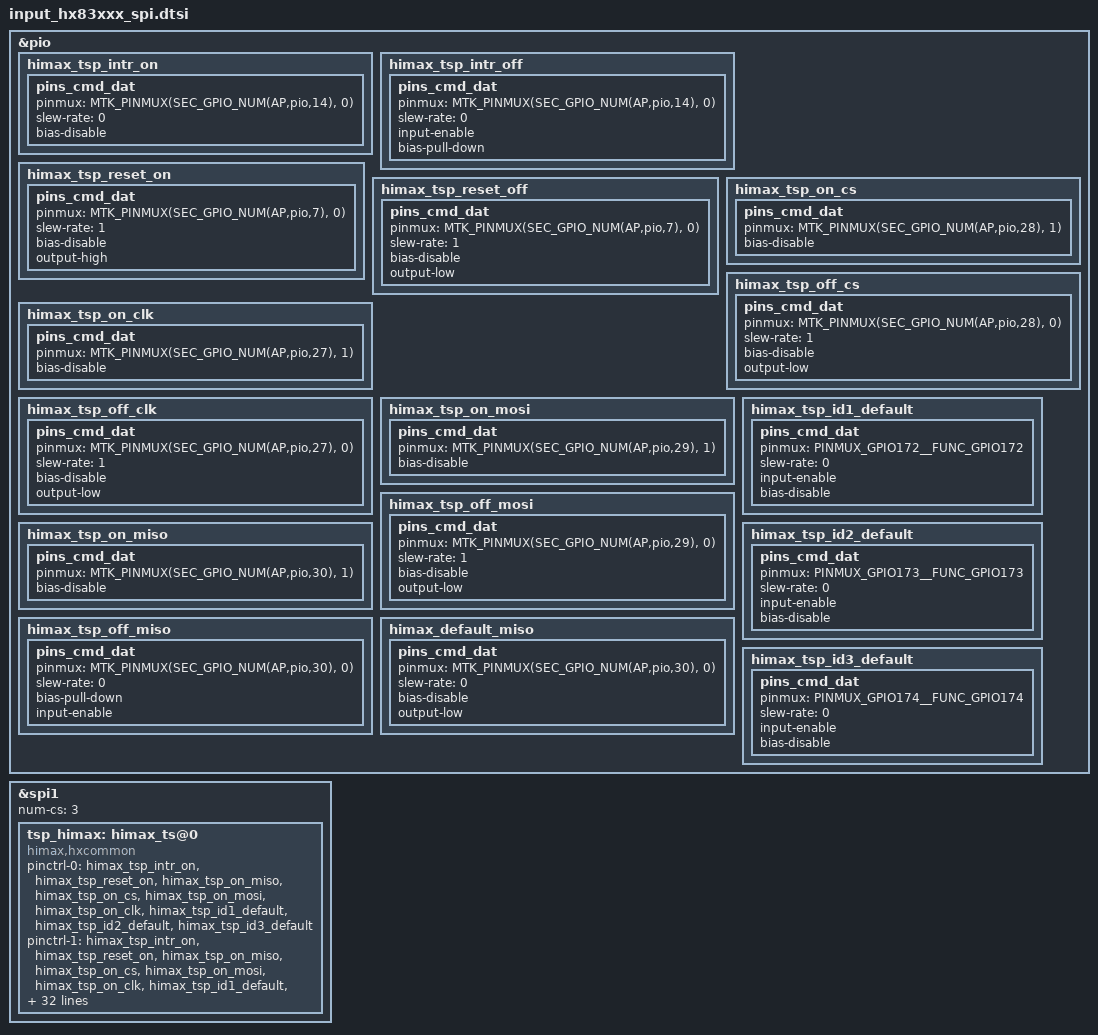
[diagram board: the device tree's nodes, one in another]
/* NEED TO FIX IF YOU WANT USE THIS */

&pio {
	himax_tsp_intr_on: himax_tsp_intr_on {
		pins_cmd_dat {
			pinmux = <MTK_PINMUX(SEC_GPIO_NUM(AP,pio,14), 0)>;
			slew-rate = <0>;
			bias-disable;
		};
	};

	himax_tsp_intr_off: himax_tsp_intr_off {
		pins_cmd_dat {
			pinmux = <MTK_PINMUX(SEC_GPIO_NUM(AP,pio,14), 0)>;
			slew-rate = <0>;
			input-enable;
			bias-pull-down;
		};
	};
};
&pio {
	himax_tsp_reset_on: himax_tsp_reset_on {
		pins_cmd_dat{
			pinmux = <MTK_PINMUX(SEC_GPIO_NUM(AP,pio,7), 0)>;
			slew-rate = <1>;
			bias-disable;
			output-high;
		};
	};

	himax_tsp_reset_off: himax_tsp_reset_off {
		pins_cmd_dat{
			pinmux = <MTK_PINMUX(SEC_GPIO_NUM(AP,pio,7), 0)>;
			slew-rate = <1>;
			bias-disable;
			output-low;
		};
	};
};
&pio {
	himax_tsp_on_cs: himax_tsp_on_cs {
		pins_cmd_dat{
			pinmux = <MTK_PINMUX(SEC_GPIO_NUM(AP,pio,28), 1)>;
			bias-disable;
		};
	};
	himax_tsp_off_cs: himax_tsp_off_cs {
		pins_cmd_dat{
			pinmux = <MTK_PINMUX(SEC_GPIO_NUM(AP,pio,28), 0)>;
			slew-rate = <1>;
			bias-disable;
			output-low;
		};
	};
};
&pio {
	himax_tsp_on_clk: himax_tsp_on_clk {
		pins_cmd_dat{
			pinmux = <MTK_PINMUX(SEC_GPIO_NUM(AP,pio,27), 1)>;
			bias-disable;
		};
	};
	himax_tsp_off_clk: himax_tsp_off_clk {
		pins_cmd_dat{
			pinmux = <MTK_PINMUX(SEC_GPIO_NUM(AP,pio,27), 0)>;
			slew-rate = <1>;
			bias-disable;
			output-low;
		};
	};

	himax_tsp_on_mosi: himax_tsp_on_mosi {
		pins_cmd_dat{
			pinmux = <MTK_PINMUX(SEC_GPIO_NUM(AP,pio,29), 1)>;
			bias-disable;
		};
	};
	himax_tsp_off_mosi: himax_tsp_off_mosi {
		pins_cmd_dat{
			pinmux = <MTK_PINMUX(SEC_GPIO_NUM(AP,pio,29), 0)>;
			slew-rate = <1>;
			bias-disable;
			output-low;
		};
	};

	himax_tsp_on_miso: himax_tsp_on_miso {
		pins_cmd_dat{
			pinmux = <MTK_PINMUX(SEC_GPIO_NUM(AP,pio,30), 1)>;
			bias-disable;
		};
	};

	himax_tsp_off_miso: himax_tsp_off_miso {
		pins_cmd_dat{
			pinmux = <MTK_PINMUX(SEC_GPIO_NUM(AP,pio,30), 0)>;
			slew-rate = <0>;
			bias-pull-down;
			input-enable;
		};
	};

	himax_default_miso: himax_default_miso {
		pins_cmd_dat{
			pinmux = <MTK_PINMUX(SEC_GPIO_NUM(AP,pio,30), 0)>;
			slew-rate = <0>;
			bias-disable;
			output-low;
		};
	};
};

&spi1 {
	status = "okay";
	#address-cells = <1>;
	#size-cells = <0>;
	num-cs = <1>;
	tsp_himax: himax_ts@0 {
		compatible = "himax,hxcommon";

		pinctrl-names = "default", "on_state", "off_state";
		pinctrl-0 = <&himax_tsp_intr_on &himax_tsp_reset_on &himax_tsp_on_miso &himax_tsp_on_cs &himax_tsp_on_mosi &himax_tsp_on_clk>;
		pinctrl-1 = <&himax_tsp_intr_on &himax_tsp_reset_on &himax_tsp_on_miso &himax_tsp_on_cs &himax_tsp_on_mosi &himax_tsp_on_clk>;
		pinctrl-2 = <&himax_tsp_intr_off &himax_tsp_off_miso &himax_tsp_off_cs &himax_tsp_off_mosi &himax_tsp_off_clk>;
		//&reset_off need to control at driver, spi low -> need 1frame delay -> tsp_reset low.

		reg = <0>; //Same as CS ID
		spi-max-frequency = <10000000>;
		himax,rst-gpio = <SEC_GPIO_REF(AP,pio,7) 0x00>;
		himax,irq-gpio = <SEC_GPIO_REF(AP,pio,14) 0x00>;

		himax,enable_sysinput_enabled;
	};
};

/* /home/dpi/qb5_8814/workspace/P4_1716/android/kernel/kmodule/input/touchscreen/himax/hx83xxx_spi/dts/input-mtk-tsp-hx83xxx_spi.a13x.dtsi */
&pio {
	himax_tsp_id1_default: himax_tsp_id1_default {
		pins_cmd_dat {
			pinmux = <PINMUX_GPIO172__FUNC_GPIO172>;
			slew-rate = <0>;
			input-enable;
			bias-disable;
		};
	};

	himax_tsp_id2_default: himax_tsp_id2_default {
		pins_cmd_dat {
			pinmux = <PINMUX_GPIO173__FUNC_GPIO173>;
			slew-rate = <0>;
			input-enable;
			bias-disable;
		};
	};

	himax_tsp_id3_default: himax_tsp_id3_default {
		pins_cmd_dat {
			pinmux = <PINMUX_GPIO174__FUNC_GPIO174>;
			slew-rate = <0>;
			input-enable;
			bias-disable;
		};
	};
};

&spi1 {
	num-cs = <3>;
};
&tsp_himax{
	pinctrl-names = "default", "on_state", "off_state";
	pinctrl-0 = <&himax_tsp_intr_on &himax_tsp_reset_on &himax_tsp_on_miso &himax_tsp_on_cs &himax_tsp_on_mosi &himax_tsp_on_clk &himax_tsp_id1_default &himax_tsp_id2_default &himax_tsp_id3_default>;
	pinctrl-1 = <&himax_tsp_intr_on &himax_tsp_reset_on &himax_tsp_on_miso &himax_tsp_on_cs &himax_tsp_on_mosi &himax_tsp_on_clk &himax_tsp_id1_default &himax_tsp_id2_default &himax_tsp_id3_default>;
	pinctrl-2 = <&himax_tsp_intr_off &himax_tsp_off_miso &himax_tsp_off_cs &himax_tsp_off_mosi &himax_tsp_off_clk &himax_tsp_id1_default &himax_tsp_id2_default &himax_tsp_id3_default>;
	//&reset_off need to control at driver, spi low -> need 1frame delay -> tsp_reset low.

	himax,panel-coords = <720 1600>;
	himax,display-coords = <720 1600>;
	himax,notch-setting = <287 319>;
	himax,fix_touch_info = <32 18 0 720 1600 10 1 1>;
	//FIX_HX_RX_NUM,FIX_HX_TX_NUM,FIX_HX_BT_NUM,FIX_HX_X_RES,FIX_HX_Y_RES,FIX_HX_MAX_PT,FIX_HX_XY_REVERSE
	himax,project_name = "A13X", "A136";

	support_aot;
	himax,support_ear_detect_mode;
	himax,support_spay_gesture_mode;
	himax,prox_lp_scan_enabled;

	himax,lcdid1-gpio = <&pio 172 0x0>;
	himax,lcdid2-gpio = <&pio 173 0x0>;
	himax,lcdid3-gpio = <&pio 174 0x0>;
	himax,lcdid = <5>;	// 0,0,0,0,0,BOE_Himax
	himax,lcdtype = <0 0 0 0 0 0x2a6234>;
	himax,fw_name = "","","","","","tsp_himax/hx83108a_a13x.bin";

	himax,name_lcd_vddi = "vcamio";
	himax,name_lcd_rst = "gpio_lcd_rst";
	himax,name_lcd_bl_en = "gpio_lcd_bl_en";
	himax,one_frame_delay = <20>;
	himax,report_type = <1>;
};
